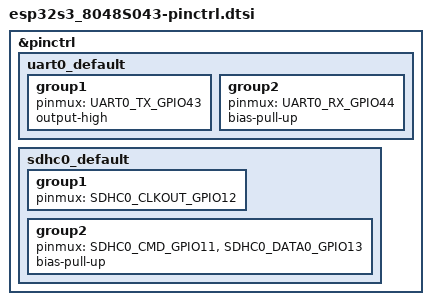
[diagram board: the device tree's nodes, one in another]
#include <zephyr/dt-bindings/pinctrl/esp32s3-pinctrl.h>

&pinctrl {
	uart0_default: uart0_default {
		group1 {
			pinmux = <UART0_TX_GPIO43>;
			output-high;
		};

		group2 {
			pinmux = <UART0_RX_GPIO44>;
			bias-pull-up;
		};
	};

	sdhc0_default: sdhc0_default {
		group1 {
			pinmux = <SDHC0_CLKOUT_GPIO12>;
		};

		group2 {
			pinmux = <SDHC0_CMD_GPIO11>,
				 <SDHC0_DATA0_GPIO13>;
			bias-pull-up;
		};
	};
};
